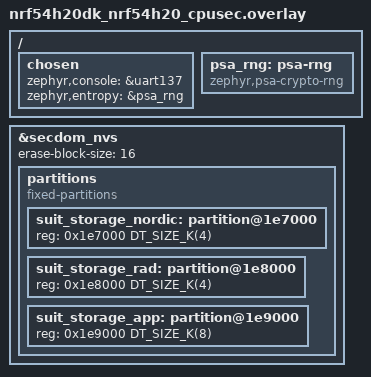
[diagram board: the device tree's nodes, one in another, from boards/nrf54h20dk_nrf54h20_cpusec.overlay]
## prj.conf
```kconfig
#
# Copyright (c) 2024 Nordic Semiconductor ASA
#
# SPDX-License-Identifier: LicenseRef-Nordic-5-Clause
#

CONFIG_ZTEST=y
CONFIG_ZTEST_NEW_API=y

CONFIG_SUIT=y
CONFIG_SUIT_UTILS=y
CONFIG_SUIT_STORAGE=y
# Force SUIT storage memory layout to match nRF54H20-specific implementation.
CONFIG_SUIT_STORAGE_LAYOUT_NRF54H20=y
CONFIG_SUIT_METADATA=y
# nRF54H20 storage uses SHA-256 to protect MPI and NVVs:
CONFIG_SUIT_CRYPTO=y

CONFIG_ZCBOR=y
CONFIG_ZCBOR_CANONICAL=y

CONFIG_FLASH=y
```

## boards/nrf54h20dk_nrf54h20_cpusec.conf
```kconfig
#
# Copyright (c) 2024 Nordic Semiconductor ASA
#
# SPDX-License-Identifier: LicenseRef-Nordic-5-Clause
#

CONFIG_NULL_POINTER_EXCEPTION_DETECTION_NONE=y
CONFIG_SERIAL=y
CONFIG_CONSOLE=y
CONFIG_UART_CONSOLE=y

# This test does not set 'IS_SECURE_DOMAIN_FW'. Hence, we need to enable the
# bare minimum configurations for running on bare metal Secure Domain.
CONFIG_SECDOM_UNIT_TEST_SUPPORT=y

# Logging and printk is using standard UART.
CONFIG_LOG_MODE_DEFERRED=y
CONFIG_LOG_BACKEND_UART=y
CONFIG_LOG_PRINTK=y
CONFIG_LOG_BUFFER_SIZE=8192
```

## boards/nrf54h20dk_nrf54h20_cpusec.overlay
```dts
/*
 * Copyright (c) 2024 Nordic Semiconductor ASA
 *
 * SPDX-License-Identifier: LicenseRef-Nordic-5-Clause
 */

/ {
	chosen {
		zephyr,console = &uart137;
		zephyr,entropy = &psa_rng;
	};

	psa_rng: psa-rng {
		compatible = "zephyr,psa-crypto-rng";
		status = "okay";
	};
};

&secdom_nvs {
	erase-block-size = <16>;

	partitions {
		compatible = "fixed-partitions";
		#address-cells = <1>;
		#size-cells = <1>;

		/* Use the last 32 kB of SecDom SUIT NVM storage. */
		/* Use the first 4kB as area reserved for Secure domain. */
		suit_storage_nordic: partition@1e7000 {
			reg = <0x1e7000 DT_SIZE_K(4)>;
		};

		/* Use the next 4kB as area reserved for Radio domain. */
		suit_storage_rad: partition@1e8000 {
			reg = <0x1e8000 DT_SIZE_K(4)>;
		};

		/* Use the next 8kB as area reserved for Application domain. */
		suit_storage_app: partition@1e9000 {
			reg = <0x1e9000 DT_SIZE_K(8)>;
		};
	};
};
```

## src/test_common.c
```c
/*
 * Copyright (c) 2024 Nordic Semiconductor ASA
 *
 * SPDX-License-Identifier: LicenseRef-Nordic-5-Clause
 */

#include <zephyr/ztest.h>
#include <suit_storage_mpi.h>
#include "test_common.h"

/* RFC4122 uuid5(uuid.NAMESPACE_DNS, 'nordicsemi.com') */
static uint8_t nordic_vid[] = {
	0x76, 0x17, 0xda, 0xa5, 0x71, 0xfd, 0x5a, 0x85,
	0x8f, 0x94, 0xe2, 0x8d, 0x73, 0x5c, 0xe9, 0xf4
};

/* RFC4122 uuid5(nordic_vid, 'nRF54H20_nordic_top') */
static uint8_t nordic_top_cid[] = {
	0xf0, 0x3d, 0x38, 0x5e, 0xa7, 0x31, 0x56, 0x05,
	0xb1, 0x5d, 0x03, 0x7f, 0x6d, 0xa6, 0x09, 0x7f
};

/* RFC4122 uuid5(nordic_vid, 'nRF54H20_sec') */
static uint8_t nordic_sdfw_cid[] = {
	0xd9, 0x6b, 0x40, 0xb7, 0x09, 0x2b, 0x5c, 0xd1,
	0xa5, 0x9f, 0x9a, 0xf8, 0x0c, 0x33, 0x7e, 0xba
};

/* RFC4122 uuid5(nordic_vid, 'nRF54H20_sys') */
static uint8_t nordic_scfw_cid[] = {
	0xc0, 0x8a, 0x25, 0xd7, 0x35, 0xe6, 0x59, 0x2c,
	0xb7, 0xad, 0x43, 0xac, 0xc8, 0xd1, 0xd1, 0xc8
};

/* RFC4122 uuid5(nordic_vid, 'test_sample_root') */
static uint8_t app_root_cid[] = {
	0x97, 0x05, 0x48, 0x23, 0x4c, 0x3d, 0x59, 0xa1,
	0x89, 0x86, 0xa5, 0x46, 0x60, 0xa1, 0x4b, 0x0a,
};

uint8_t nvv_empty[64] = {
	/* 0xFF * 32 */
	0xFF, 0xFF, 0xFF, 0xFF, 0xFF, 0xFF, 0xFF, 0xFF,
	0xFF, 0xFF, 0xFF, 0xFF, 0xFF, 0xFF, 0xFF, 0xFF,
	0xFF, 0xFF, 0xFF, 0xFF, 0xFF, 0xFF, 0xFF, 0xFF,
	0xFF, 0xFF, 0xFF, 0xFF, 0xFF, 0xFF, 0xFF, 0xFF,
	/* SHA-256 */
	0xAF, 0x96, 0x13, 0x76, 0x0F, 0x72, 0x63, 0x5F,
	0xBD, 0xB4, 0x4A, 0x5A, 0x0A, 0x63, 0xC3, 0x9F,
	0x12, 0xAF, 0x30, 0xF9, 0x50, 0xA6, 0xEE, 0x5C,
	0x97, 0x1B, 0xE1, 0x88, 0xE8, 0x9C, 0x40, 0x51,
};

uint8_t nvv_sample[64] = {
	/* sample 8 values */
	0x00, 0x00, 0x00, 0x00, 0xAA, 0xAA, 0xAA, 0xAA,
	0xAA, 0x55, 0xAA, 0x55, 0x00, 0x00, 0x00, 0x01,
	0x01, 0x00, 0x00, 0x00, 0xFF, 0xFF, 0xFF, 0xFF,
	0xAB, 0xCD, 0xEF, 0x98, 0xFF, 0xFF, 0xFF, 0xFF,
	/* SHA-256 */
	0x73, 0xb4, 0x25, 0x20, 0xdf, 0x43, 0x7e, 0xc7,
	0x63, 0xfb, 0xb6, 0x05, 0x70, 0x23, 0x2f, 0xb3,
	0x6a, 0x65, 0xbe, 0x14, 0xcb, 0x2e, 0x83, 0x6a,
	0x3b, 0xc9, 0xfd, 0x87, 0xf6, 0xde, 0x79, 0x05,
};

void erase_area_nordic(void)
{
	/* Clear the whole nordic area */
	const struct device *fdev = DEVICE_DT_GET(DT_CHOSEN(zephyr_flash_controller));
	zassert_not_null(fdev, "Unable to find a driver to modify MPI area");

	int err = flash_erase(fdev, SUIT_STORAGE_NORDIC_OFFSET, SUIT_STORAGE_NORDIC_SIZE);
	zassert_equal(0, err, "Unable to erase nordic area before test execution");
}

void erase_area_rad(void)
{
	/* Clear the whole radio area */
	const struct device *fdev = DEVICE_DT_GET(DT_CHOSEN(zephyr_flash_controller));
	zassert_not_null(fdev, "Unable to find a driver to modify MPI area");

	int err = flash_erase(fdev, SUIT_STORAGE_RAD_OFFSET, SUIT_STORAGE_RAD_SIZE);
	zassert_equal(0, err, "Unable to erase radio core area before test execution");
}

void erase_area_app(void)
{
	/* Clear the whole application area */
	const struct device *fdev = DEVICE_DT_GET(DT_CHOSEN(zephyr_flash_controller));
	zassert_not_null(fdev, "Unable to find a driver to modify MPI area");

	int err = flash_erase(fdev, SUIT_STORAGE_APP_OFFSET, SUIT_STORAGE_APP_SIZE);
	zassert_equal(0, err, "Unable to erase application area before test execution");
}

void erase_area_app_nvv(void)
{
	const struct device *fdev = DEVICE_DT_GET(DT_CHOSEN(zephyr_flash_controller));
	zassert_not_null(fdev, "Unable to find a driver to modify MPI area");

	int err = flash_erase(fdev, SUIT_STORAGE_APP_NVV_OFFSET, SUIT_STORAGE_APP_NVV_SIZE / 2);
	zassert_equal(0, err, "Unable to erase NNV area before test execution");
}

void erase_area_app_nvv_backup(void)
{
	const struct device *fdev = DEVICE_DT_GET(DT_CHOSEN(zephyr_flash_controller));
	zassert_not_null(fdev, "Unable to find a driver to modify MPI area");

	int err = flash_erase(fdev, SUIT_STORAGE_APP_NVV_OFFSET + SUIT_STORAGE_APP_NVV_SIZE / 2,
			      SUIT_STORAGE_APP_NVV_SIZE / 2);
	zassert_equal(0, err, "Unable to erase NNV backup before test execution");
}

void write_area_app_empty_nvv_backup(void)
{
	const struct device *fdev = DEVICE_DT_GET(DT_CHOSEN(zephyr_flash_controller));
	zassert_not_null(fdev, "Unable to find a driver to modify MPI area");

	int err = flash_write(fdev, SUIT_STORAGE_APP_NVV_OFFSET + SUIT_STORAGE_APP_NVV_SIZE / 2,
			      nvv_empty, sizeof(nvv_empty));
	zassert_equal(0, err, "Unable to store empty NVV contents before test execution");
}

void write_area_app_nvv_backup(void)
{
	const struct device *fdev = DEVICE_DT_GET(DT_CHOSEN(zephyr_flash_controller));
	zassert_not_null(fdev, "Unable to find a driver to modify MPI area");

	int err = flash_write(fdev, SUIT_STORAGE_APP_NVV_OFFSET + SUIT_STORAGE_APP_NVV_SIZE / 2,
			      nvv_sample, sizeof(nvv_sample));
	zassert_equal(0, err, "Unable to store empty NVV contents before test execution");
}

void write_area_app_nvv(void)
{
	const struct device *fdev = DEVICE_DT_GET(DT_CHOSEN(zephyr_flash_controller));
	zassert_not_null(fdev, "Unable to find a driver to modify MPI area");

	int err = flash_write(fdev, SUIT_STORAGE_APP_NVV_OFFSET, nvv_sample, sizeof(nvv_sample));
	zassert_equal(0, err, "Unable to store sample NVV contents before test execution");
}

void write_empty_area_app(void)
{
	/* Digest of the content defined in assert_empty_mpi_area_app(). */
	uint8_t app_digest[] = {
		0xd6, 0xc4, 0x94, 0x17, 0xb1, 0xca, 0x0a, 0x67,
		0x14, 0xdc, 0xde, 0x2b, 0x40, 0x01, 0x0c, 0xb7,
		0x49, 0x6d, 0x05, 0xdf, 0x7f, 0x8c, 0x8b, 0x1b,
		0x98, 0x14, 0x09, 0x7e, 0x9d, 0x62, 0xc8, 0xe1,
	};

	/* Write the digest of application area filled with 0xFF */
	const struct device *fdev = DEVICE_DT_GET(DT_CHOSEN(zephyr_flash_controller));
	zassert_not_null(fdev, "Unable to find a driver to modify MPI area");

	int err = flash_write(fdev, SUIT_STORAGE_APP_OFFSET + SUIT_STORAGE_APP_MPI_SIZE, app_digest,
			      sizeof(app_digest));
	zassert_equal(0, err, "Unable to store application MPI digest before test execution");
}

void write_area_app_root(void)
{
	uint8_t mpi_root[] = {
		0x01, /* version */
		0x01, /* downgrade prevention disabled */
		0x02, /* Independent update allowed */
		0x01, /* signature check disabled */
		/* reserved (12) */
		0xFF, 0xFF, 0xFF, 0xFF,
		0xFF, 0xFF, 0xFF, 0xFF, 0xFF, 0xFF, 0xFF, 0xFF,
		/* RFC4122 uuid5(uuid.NAMESPACE_DNS, 'nordicsemi.com') */
		0x76, 0x17, 0xda, 0xa5, 0x71, 0xfd, 0x5a, 0x85,
		0x8f, 0x94, 0xe2, 0x8d, 0x73, 0x5c, 0xe9, 0xf4,
		/* RFC4122 uuid5(nordic_vid, 'test_sample_root') */
		0x97, 0x05, 0x48, 0x23, 0x4c, 0x3d, 0x59, 0xa1,
		0x89, 0x86, 0xa5, 0x46, 0x60, 0xa1, 0x4b, 0x0a,
	};
	/* Digest of the content defined in assert_valid_mpi_area_app(). */
	uint8_t app_digest[] = {
		0xa9, 0xa0, 0xee, 0x40, 0x5f, 0xad, 0x2b, 0xeb,
		0x66, 0x50, 0xdd, 0xa9, 0x97, 0x11, 0x72, 0x98,
		0x2b, 0x17, 0x45, 0x90, 0x16, 0xe1, 0xc7, 0xf5,
		0xc1, 0xdc, 0x3f, 0xb4, 0x58, 0x96, 0x1e, 0x44,
	};

	/* Write the sample application area (just the root MPI) and corresponding digest */
	const struct device *fdev = DEVICE_DT_GET(DT_CHOSEN(zephyr_flash_controller));
	zassert_not_null(fdev, "Unable to find a driver to modify MPI area");

	int err = flash_write(fdev, SUIT_STORAGE_APP_OFFSET, mpi_root, sizeof(mpi_root));
	zassert_equal(0, err,
		      "Unable to store application root MPI contents before test execution");

	err = flash_write(fdev, SUIT_STORAGE_APP_OFFSET + SUIT_STORAGE_APP_MPI_SIZE, app_digest,
			  sizeof(app_digest));
	zassert_equal(0, err, "Unable to store application MPI digest before test execution");
}

void write_area_nordic_root(void)
{
	uintptr_t mpi_root_backup_offset = SUIT_STORAGE_NORDIC_OFFSET + SUIT_STORAGE_RAD_MPI_SIZE;
	uint8_t mpi_root[] = {
		0x01, /* version */
		0x01, /* downgrade prevention disabled */
		0x02, /* Independent update allowed */
		0x01, /* signature check disabled */
		/* reserved (12) */
		0xFF, 0xFF, 0xFF, 0xFF,
		0xFF, 0xFF, 0xFF, 0xFF, 0xFF, 0xFF, 0xFF, 0xFF,
		/* RFC4122 uuid5(uuid.NAMESPACE_DNS, 'nordicsemi.com') */
		0x76, 0x17, 0xda, 0xa5, 0x71, 0xfd, 0x5a, 0x85,
		0x8f, 0x94, 0xe2, 0x8d, 0x73, 0x5c, 0xe9, 0xf4,
		/* RFC4122 uuid5(nordic_vid, 'test_sample_root') */
		0x97, 0x05, 0x48, 0x23, 0x4c, 0x3d, 0x59, 0xa1,
		0x89, 0x86, 0xa5, 0x46, 0x60, 0xa1, 0x4b, 0x0a,
	};
	/* Digest of the content defined in assert_valid_mpi_area_app(). */
	uint8_t app_digest[] = {
		0xa9, 0xa0, 0xee, 0x40, 0x5f, 0xad, 0x2b, 0xeb,
		0x66, 0x50, 0xdd, 0xa9, 0x97, 0x11, 0x72, 0x98,
		0x2b, 0x17, 0x45, 0x90, 0x16, 0xe1, 0xc7, 0xf5,
		0xc1, 0xdc, 0x3f, 0xb4, 0x58, 0x96, 0x1e, 0x44,
	};

	/* Write the sample application backup area (just the root MPI) and corresponding digest */
	const struct device *fdev = DEVICE_DT_GET(DT_CHOSEN(zephyr_flash_controller));
	zassert_not_null(fdev, "Unable to find a driver to modify MPI area");

	int err = flash_write(fdev, mpi_root_backup_offset, mpi_root, sizeof(mpi_root));
	zassert_equal(0, err,
		      "Unable to store application backup root MPI contents before test execution");

	err = flash_write(fdev, mpi_root_backup_offset + SUIT_STORAGE_APP_MPI_SIZE, app_digest,
			  sizeof(app_digest));
	zassert_equal(0, err,
		      "Unable to store application backup MPI digest before test execution");
}

void write_area_nordic_old_root(void)
{
	uintptr_t mpi_root_backup_offset = SUIT_STORAGE_NORDIC_OFFSET + SUIT_STORAGE_RAD_MPI_SIZE;
	uint8_t mpi_root[] = {
		0x01, /* version */
		0x01, /* downgrade prevention disabled */
		0x02, /* Independent update allowed */
		0x01, /* signature check disabled */
		/* reserved (12) */
		0xFF, 0xFF, 0xFF, 0xFF,
		0xFF, 0xFF, 0xFF, 0xFF, 0xFF, 0xFF, 0xFF, 0xFF,
		/* RFC4122 uuid5(uuid.NAMESPACE_DNS, 'nordicsemi.com') */
		0x76, 0x17, 0xda, 0xa5, 0x71, 0xfd, 0x5a, 0x85,
		0x8f, 0x94, 0xe2, 0x8d, 0x73, 0x5c, 0xe9, 0xf4,
		/* 0xAA * 16 */
		0xAA, 0xAA, 0xAA, 0xAA, 0xAA, 0xAA, 0xAA, 0xAA,
		0xAA, 0xAA, 0xAA, 0xAA, 0xAA, 0xAA, 0xAA, 0xAA,
	};
	uint8_t app_digest[] = {
		0xca, 0x4f, 0x80, 0xdc, 0xd1, 0x9b, 0xb2, 0x24,
		0x8e, 0x2b, 0x13, 0xeb, 0x6c, 0xf2, 0xae, 0xd0,
		0x96, 0x28, 0xc2, 0x0c, 0x69, 0xe5, 0xf5, 0x23,
		0x0c, 0x92, 0xd6, 0x2d, 0x36, 0x69, 0x27, 0x58,
	};

	/* Write the sample application backup area (just the root MPI with altered class) and
	 * corresponding digest */
	const struct device *fdev = DEVICE_DT_GET(DT_CHOSEN(zephyr_flash_controller));
	zassert_not_null(fdev, "Unable to find a driver to modify MPI area");

	int err = flash_write(fdev, mpi_root_backup_offset, mpi_root, sizeof(mpi_root));
	zassert_equal(0, err,
		      "Unable to store application backup root MPI contents before test execution");

	err = flash_write(fdev, mpi_root_backup_offset + SUIT_STORAGE_APP_MPI_SIZE, app_digest,
			  sizeof(app_digest));
	zassert_equal(0, err,
		      "Unable to store application backup MPI digest before test execution");
}

void assert_nordic_classes(void)
{
	suit_manifest_class_info_t class_infos[CONFIG_SUIT_STORAGE_N_ENVELOPES];
	size_t class_infos_len = CONFIG_SUIT_STORAGE_N_ENVELOPES;

	/* ASSERT that it is possible to fetch list of supported manifest classes and roles */
	int err = suit_storage_mpi_class_ids_get(class_infos, &class_infos_len);
	zassert_equal(err, SUIT_PLAT_SUCCESS,
		      "Failed to fetch list of supported manifest classes (%d).", err);
	/* ... and MPI reports at least 3 class IDs */
	zassert_true(class_infos_len >= 3,
		     "Invalid number of supported manifest classes (%d < %d).", err, 3);
	/* ... and the Nordic top manifest class is supported */
	zassert_mem_equal(class_infos[0].vendor_id, nordic_vid, sizeof(nordic_vid));
	zassert_mem_equal(class_infos[0].class_id, nordic_top_cid, sizeof(nordic_top_cid));
	zassert_equal(class_infos[0].role, SUIT_MANIFEST_SEC_TOP, "Invalid class role returned: %d",
		      class_infos[0].role);
	/* ... and the Nordic secure domain update & recovery manifest class is supported */
	zassert_mem_equal(class_infos[1].vendor_id, nordic_vid, sizeof(nordic_vid));
	zassert_mem_equal(class_infos[1].class_id, nordic_sdfw_cid, sizeof(nordic_sdfw_cid));
	zassert_equal(class_infos[1].role, SUIT_MANIFEST_SEC_SDFW,
		      "Invalid class role returned: %d", class_infos[3].role);
	/* ... and the Nordic system controller manifest class is supported */
	zassert_mem_equal(class_infos[2].vendor_id, nordic_vid, sizeof(nordic_vid));
	zassert_mem_equal(class_infos[2].class_id, nordic_scfw_cid, sizeof(nordic_scfw_cid));
	zassert_equal(class_infos[2].role, SUIT_MANIFEST_SEC_SYSCTRL,
		      "Invalid class role returned: %d", class_infos[3].role);
}

void assert_sample_root_class(void)
{
	suit_manifest_class_info_t class_infos[CONFIG_SUIT_STORAGE_N_ENVELOPES];
	size_t class_infos_len = CONFIG_SUIT_STORAGE_N_ENVELOPES;

	/* ASSERT that it is possible to fetch list of supported manifest classes and roles */
	int err = suit_storage_mpi_class_ids_get(class_infos, &class_infos_len);
	zassert_equal(err, SUIT_PLAT_SUCCESS,
		      "Failed to fetch list of supported manifest classes (%d).", err);
	/* ... and MPI reports 4 supported class IDs */
	zassert_equal(class_infos_len, 4,
		      "Invalid number of supported manifest classes (%d != %d).", err, 4);
	/* ... and the sample application root manifest class is supported */
	zassert_mem_equal(class_infos[3].vendor_id, nordic_vid, sizeof(nordic_vid));
	zassert_mem_equal(class_infos[3].class_id, app_root_cid, sizeof(app_root_cid));
	zassert_equal(class_infos[3].role, SUIT_MANIFEST_APP_ROOT,
		      "Invalid class role returned: %d", class_infos[3].role);
}

void assert_empty_mpi_area_app(uint8_t *addr, size_t size)
{
	uint8_t empty_mpi_app[] = {
		/* 0xFF * 240 */
		0xFF, 0xFF, 0xFF, 0xFF, 0xFF, 0xFF, 0xFF, 0xFF,
		0xFF, 0xFF, 0xFF, 0xFF, 0xFF, 0xFF, 0xFF, 0xFF,
		0xFF, 0xFF, 0xFF, 0xFF, 0xFF, 0xFF, 0xFF, 0xFF,
		0xFF, 0xFF, 0xFF, 0xFF, 0xFF, 0xFF, 0xFF, 0xFF,
		0xFF, 0xFF, 0xFF, 0xFF, 0xFF, 0xFF, 0xFF, 0xFF,
		0xFF, 0xFF, 0xFF, 0xFF, 0xFF, 0xFF, 0xFF, 0xFF,
		0xFF, 0xFF, 0xFF, 0xFF, 0xFF, 0xFF, 0xFF, 0xFF,
		0xFF, 0xFF, 0xFF, 0xFF, 0xFF, 0xFF, 0xFF, 0xFF,
		0xFF, 0xFF, 0xFF, 0xFF, 0xFF, 0xFF, 0xFF, 0xFF,
		0xFF, 0xFF, 0xFF, 0xFF, 0xFF, 0xFF, 0xFF, 0xFF,
		0xFF, 0xFF, 0xFF, 0xFF, 0xFF, 0xFF, 0xFF, 0xFF,
		0xFF, 0xFF, 0xFF, 0xFF, 0xFF, 0xFF, 0xFF, 0xFF,
		0xFF, 0xFF, 0xFF, 0xFF, 0xFF, 0xFF, 0xFF, 0xFF,
		0xFF, 0xFF, 0xFF, 0xFF, 0xFF, 0xFF, 0xFF, 0xFF,
		0xFF, 0xFF, 0xFF, 0xFF, 0xFF, 0xFF, 0xFF, 0xFF,
		0xFF, 0xFF, 0xFF, 0xFF, 0xFF, 0xFF, 0xFF, 0xFF,
		0xFF, 0xFF, 0xFF, 0xFF, 0xFF, 0xFF, 0xFF, 0xFF,
		0xFF, 0xFF, 0xFF, 0xFF, 0xFF, 0xFF, 0xFF, 0xFF,
		0xFF, 0xFF, 0xFF, 0xFF, 0xFF, 0xFF, 0xFF, 0xFF,
		0xFF, 0xFF, 0xFF, 0xFF, 0xFF, 0xFF, 0xFF, 0xFF,
		0xFF, 0xFF, 0xFF, 0xFF, 0xFF, 0xFF, 0xFF, 0xFF,
		0xFF, 0xFF, 0xFF, 0xFF, 0xFF, 0xFF, 0xFF, 0xFF,
		0xFF, 0xFF, 0xFF, 0xFF, 0xFF, 0xFF, 0xFF, 0xFF,
		0xFF, 0xFF, 0xFF, 0xFF, 0xFF, 0xFF, 0xFF, 0xFF,
		0xFF, 0xFF, 0xFF, 0xFF, 0xFF, 0xFF, 0xFF, 0xFF,
		0xFF, 0xFF, 0xFF, 0xFF, 0xFF, 0xFF, 0xFF, 0xFF,
		0xFF, 0xFF, 0xFF, 0xFF, 0xFF, 0xFF, 0xFF, 0xFF,
		0xFF, 0xFF, 0xFF, 0xFF, 0xFF, 0xFF, 0xFF, 0xFF,
		0xFF, 0xFF, 0xFF, 0xFF, 0xFF, 0xFF, 0xFF, 0xFF,
		0xFF, 0xFF, 0xFF, 0xFF, 0xFF, 0xFF, 0xFF, 0xFF,
		/* SHA-256 */
		0xd6, 0xc4, 0x94, 0x17, 0xb1, 0xca, 0x0a, 0x67,
		0x14, 0xdc, 0xde, 0x2b, 0x40, 0x01, 0x0c, 0xb7,
		0x49, 0x6d, 0x05, 0xdf, 0x7f, 0x8c, 0x8b, 0x1b,
		0x98, 0x14, 0x09, 0x7e, 0x9d, 0x62, 0xc8, 0xe1,
	};

	zassert_equal(size, sizeof(empty_mpi_app), "Incorrect area size (0x%x != 0x%x)", size,
		      sizeof(empty_mpi_app));
	zassert_mem_equal(addr, empty_mpi_app, sizeof(empty_mpi_app),
			  "MPI area does not match empty contents (addr: 0x%lx)", (uintptr_t)addr);
}

void assert_valid_mpi_area_app(uint8_t *addr, size_t size)
{
	uint8_t valid_mpi_app[] = {
		0x01, /* version */
		0x01, /* downgrade prevention disabled */
		0x02, /* Independent update allowed */
		0x01, /* signature check disabled */
		/* reserved (12) */
		0xFF, 0xFF, 0xFF, 0xFF,
		0xFF, 0xFF, 0xFF, 0xFF, 0xFF, 0xFF, 0xFF, 0xFF,
		/* RFC4122 uuid5(uuid.NAMESPACE_DNS, 'nordicsemi.com') */
		0x76, 0x17, 0xda, 0xa5, 0x71, 0xfd, 0x5a, 0x85,
		0x8f, 0x94, 0xe2, 0x8d, 0x73, 0x5c, 0xe9, 0xf4,
		/* RFC4122 uuid5(nordic_vid, 'test_sample_root') */
		0x97, 0x05, 0x48, 0x23, 0x4c, 0x3d, 0x59, 0xa1,
		0x89, 0x86, 0xa5, 0x46, 0x60, 0xa1, 0x4b, 0x0a,
		/* 0xFF * 192 */
		0xFF, 0xFF, 0xFF, 0xFF, 0xFF, 0xFF, 0xFF, 0xFF,
		0xFF, 0xFF, 0xFF, 0xFF, 0xFF, 0xFF, 0xFF, 0xFF,
		0xFF, 0xFF, 0xFF, 0xFF, 0xFF, 0xFF, 0xFF, 0xFF,
		0xFF, 0xFF, 0xFF, 0xFF, 0xFF, 0xFF, 0xFF, 0xFF,
		0xFF, 0xFF, 0xFF, 0xFF, 0xFF, 0xFF, 0xFF, 0xFF,
		0xFF, 0xFF, 0xFF, 0xFF, 0xFF, 0xFF, 0xFF, 0xFF,
		0xFF, 0xFF, 0xFF, 0xFF, 0xFF, 0xFF, 0xFF, 0xFF,
		0xFF, 0xFF, 0xFF, 0xFF, 0xFF, 0xFF, 0xFF, 0xFF,
		0xFF, 0xFF, 0xFF, 0xFF, 0xFF, 0xFF, 0xFF, 0xFF,
		0xFF, 0xFF, 0xFF, 0xFF, 0xFF, 0xFF, 0xFF, 0xFF,
		0xFF, 0xFF, 0xFF, 0xFF, 0xFF, 0xFF, 0xFF, 0xFF,
		0xFF, 0xFF, 0xFF, 0xFF, 0xFF, 0xFF, 0xFF, 0xFF,
		0xFF, 0xFF, 0xFF, 0xFF, 0xFF, 0xFF, 0xFF, 0xFF,
		0xFF, 0xFF, 0xFF, 0xFF, 0xFF, 0xFF, 0xFF, 0xFF,
		0xFF, 0xFF, 0xFF, 0xFF, 0xFF, 0xFF, 0xFF, 0xFF,
		0xFF, 0xFF, 0xFF, 0xFF, 0xFF, 0xFF, 0xFF, 0xFF,
		0xFF, 0xFF, 0xFF, 0xFF, 0xFF, 0xFF, 0xFF, 0xFF,
		0xFF, 0xFF, 0xFF, 0xFF, 0xFF, 0xFF, 0xFF, 0xFF,
		0xFF, 0xFF, 0xFF, 0xFF, 0xFF, 0xFF, 0xFF, 0xFF,
		0xFF, 0xFF, 0xFF, 0xFF, 0xFF, 0xFF, 0xFF, 0xFF,
		0xFF, 0xFF, 0xFF, 0xFF, 0xFF, 0xFF, 0xFF, 0xFF,
		0xFF, 0xFF, 0xFF, 0xFF, 0xFF, 0xFF, 0xFF, 0xFF,
		0xFF, 0xFF, 0xFF, 0xFF, 0xFF, 0xFF, 0xFF, 0xFF,
		0xFF, 0xFF, 0xFF, 0xFF, 0xFF, 0xFF, 0xFF, 0xFF,
		/* SHA-256 */
		0xa9, 0xa0, 0xee, 0x40, 0x5f, 0xad, 0x2b, 0xeb,
		0x66, 0x50, 0xdd, 0xa9, 0x97, 0x11, 0x72, 0x98,
		0x2b, 0x17, 0x45, 0x90, 0x16, 0xe1, 0xc7, 0xf5,
		0xc1, 0xdc, 0x3f, 0xb4, 0x58, 0x96, 0x1e, 0x44,
	};

	zassert_equal(size, sizeof(valid_mpi_app), "Incorrect area size (0x%x != 0x%x)", size,
		      sizeof(valid_mpi_app));
	zassert_mem_equal(addr, valid_mpi_app, sizeof(valid_mpi_app),
			  "MPI area does not match empty contents (addr: 0x%lx)", (uintptr_t)addr);
}
```

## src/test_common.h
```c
/*
 * Copyright (c) 2024 Nordic Semiconductor ASA
 *
 * SPDX-License-Identifier: LicenseRef-Nordic-5-Clause
 */

#include <suit_plat_mem_util.h>

#ifndef TEST_COMMON_H__
#define TEST_COMMON_H__

#define SUIT_STORAGE_NORDIC_ADDRESS suit_plat_mem_nvm_ptr_get(SUIT_STORAGE_NORDIC_OFFSET)
#define SUIT_STORAGE_NORDIC_OFFSET  FIXED_PARTITION_OFFSET(suit_storage_nordic)
#define SUIT_STORAGE_NORDIC_SIZE    FIXED_PARTITION_SIZE(suit_storage_nordic)
#define SUIT_STORAGE_RAD_ADDRESS    suit_plat_mem_nvm_ptr_get(SUIT_STORAGE_RAD_OFFSET)
#define SUIT_STORAGE_RAD_OFFSET	    FIXED_PARTITION_OFFSET(suit_storage_rad)
#define SUIT_STORAGE_RAD_SIZE	    FIXED_PARTITION_SIZE(suit_storage_rad)
#define SUIT_STORAGE_APP_ADDRESS    suit_plat_mem_nvm_ptr_get(SUIT_STORAGE_APP_OFFSET)
#define SUIT_STORAGE_APP_OFFSET	    FIXED_PARTITION_OFFSET(suit_storage_app)
#define SUIT_STORAGE_APP_SIZE	    FIXED_PARTITION_SIZE(suit_storage_app)

#define SUIT_STORAGE_APP_NVV_ADDRESS suit_plat_mem_nvm_ptr_get(SUIT_STORAGE_APP_NVV_OFFSET)
#define SUIT_STORAGE_APP_NVV_OFFSET  (SUIT_STORAGE_APP_OFFSET + 0x380)
#define SUIT_STORAGE_APP_NVV_SIZE    0x80
#define SUIT_STORAGE_APP_MPI_SIZE    0xf0
#define SUIT_STORAGE_RAD_MPI_SIZE    0xb0
#define SUIT_STORAGE_DIGEST_SIZE     0x20

extern uint8_t nvv_empty[64];
extern uint8_t nvv_sample[64];

/** @brief Erase MPI area, assigned for Nordic-controlled manifests.
 */
void erase_area_nordic(void);

/** @brief Erase MPI area, assigned for radio core manifests.
 */
void erase_area_rad(void);

/** @brief Erase MPI area, assigned for application manifests.
 */
void erase_area_app(void);

/** @brief Erase part of MPI area, holding NVV values.
 */
void erase_area_app_nvv(void);

/** @brief Erase part of MPI area, holding NVV backup.
 */
void erase_area_app_nvv_backup(void);

/** @brief Populate part of MPI area, holding NVV backup with initial values.
 */
void write_area_app_empty_nvv_backup(void);

/** @brief Populate part of MPI area, holding NVV backup with sample values.
 */
void write_area_app_nvv_backup(void);

/** @brief Populate part of MPI area, holding NVV values with sample values.
 */
void write_area_app_nvv(void);

/** @brief Populate application MPI area, with ones and the correct digest.
 */
void write_empty_area_app(void);

/** @brief Populate part of application MPI area, with sample root MPI.
 */
void write_area_app_root(void);

/** @brief Populate part of Nordic MPI area, with sample root MPI backup.
 */
void write_area_nordic_root(void);

/** @brief Populate part of Nordic MPI area, with sample outdated root MPI backup.
 */
void write_area_nordic_old_root(void);

/** @brief Assert that all Nordic-controlled MPIs are provisioned.
 */
void assert_nordic_classes(void);

/** @brief Assert that root MPI is provisioned.
 */
void assert_sample_root_class(void);

/** @brief Assert that the area contains empty MPI.
 *
 * @param[in] addr  Address of the area.
 * @param[in] size  Size of the area.
 */
void assert_empty_mpi_area_app(uint8_t *addr, size_t size);

/** @brief Assert that the area contains valid root MPI.
 *
 * @param[in] addr  Address of the area.
 * @param[in] size  Size of the area.
 */
void assert_valid_mpi_area_app(uint8_t *addr, size_t size);

#endif /* TEST_COMMON_H__ */
```

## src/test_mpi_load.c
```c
/*
 * Copyright (c) 2024 Nordic Semiconductor ASA
 *
 * SPDX-License-Identifier: LicenseRef-Nordic-5-Clause
 */

#include <zephyr/ztest.h>
#include <suit_storage_mpi.h>
#include "test_common.h"

static void test_suite_before(void *f)
{
	/* Reinitialize MPI, so it clears all internal state variables. */
	suit_plat_err_t err = suit_storage_mpi_init();
	zassert_equal(err, SUIT_PLAT_SUCCESS, "Failed to init SUIT MPI module (%d)", err);
}

ZTEST_SUITE(suit_storage_nrf54h20_mpi_load_tests, NULL, NULL, test_suite_before, NULL, NULL);

ZTEST(suit_storage_nrf54h20_mpi_load_tests, test_vid_uuid_zeros)
{
	uint8_t mpi[] = {
		0x01, /* version */
		0x01, /* downgrade prevention disabled */
		0x02, /* Independent update allowed */
		0x01, /* signature check disabled */
		/* reserved (12) */
		0xFF, 0xFF, 0xFF, 0xFF,
		0xFF, 0xFF, 0xFF, 0xFF, 0xFF, 0xFF, 0xFF, 0xFF,
		/* 0x00 * 16 */
		0x00, 0x00, 0x00, 0x00, 0x00, 0x00, 0x00, 0x00,
		0x00, 0x00, 0x00, 0x00, 0x00, 0x00, 0x00, 0x00,
		/* RFC4122 uuid5(nordic_vid, 'test_sample_root') */
		0x97, 0x05, 0x48, 0x23, 0x4c, 0x3d, 0x59, 0xa1,
		0x89, 0x86, 0xa5, 0x46, 0x60, 0xa1, 0x4b, 0x0a,
	};

	suit_plat_err_t err =
		suit_storage_mpi_configuration_load(SUIT_MANIFEST_APP_ROOT, mpi, sizeof(mpi));
	zassert_equal(err, SUIT_PLAT_ERR_OUT_OF_BOUNDS,
		      "MPI with UUID filled with zeros should fail to load");
}

ZTEST(suit_storage_nrf54h20_mpi_load_tests, test_vid_uuid_ones)
{
	uint8_t mpi[] = {
		0x01, /* version */
		0x01, /* downgrade prevention disabled */
		0x02, /* Independent update allowed */
		0x01, /* signature check disabled */
		/* reserved (12) */
		0xFF, 0xFF, 0xFF, 0xFF,
		0xFF, 0xFF, 0xFF, 0xFF, 0xFF, 0xFF, 0xFF, 0xFF,
		/* 0xFF * 16 */
		0xFF, 0xFF, 0xFF, 0xFF, 0xFF, 0xFF, 0xFF, 0xFF,
		0xFF, 0xFF, 0xFF, 0xFF, 0xFF, 0xFF, 0xFF, 0xFF,
		/* RFC4122 uuid5(nordic_vid, 'test_sample_root') */
		0x97, 0x05, 0x48, 0x23, 0x4c, 0x3d, 0x59, 0xa1,
		0x89, 0x86, 0xa5, 0x46, 0x60, 0xa1, 0x4b, 0x0a,
	};

	suit_plat_err_t err =
		suit_storage_mpi_configuration_load(SUIT_MANIFEST_APP_ROOT, mpi, sizeof(mpi));
	zassert_equal(err, SUIT_PLAT_ERR_OUT_OF_BOUNDS,
		      "MPI with UUID filled with ones should fail to load");
}

ZTEST(suit_storage_nrf54h20_mpi_load_tests, test_cid_uuid_zeros)
{
	uint8_t mpi[] = {
		0x01, /* version */
		0x01, /* downgrade prevention disabled */
		0x02, /* Independent update allowed */
		0x01, /* signature check disabled */
		/* reserved (12) */
		0xFF, 0xFF, 0xFF, 0xFF,
		0xFF, 0xFF, 0xFF, 0xFF, 0xFF, 0xFF, 0xFF, 0xFF,
		/* RFC4122 uuid5(uuid.NAMESPACE_DNS, 'nordicsemi.com') */
		0x76, 0x17, 0xda, 0xa5, 0x71, 0xfd, 0x5a, 0x85,
		0x8f, 0x94, 0xe2, 0x8d, 0x73, 0x5c, 0xe9, 0xf4,
		/* 0x00 * 16 */
		0x00, 0x00, 0x00, 0x00, 0x00, 0x00, 0x00, 0x00,
		0x00, 0x00, 0x00, 0x00, 0x00, 0x00, 0x00, 0x00,
	};

	suit_plat_err_t err =
		suit_storage_mpi_configuration_load(SUIT_MANIFEST_APP_ROOT, mpi, sizeof(mpi));
	zassert_equal(err, SUIT_PLAT_ERR_OUT_OF_BOUNDS,
		      "MPI with UUID filled with zeros should fail to load");
}

ZTEST(suit_storage_nrf54h20_mpi_load_tests, test_cid_uuid_ones)
{
	uint8_t mpi[] = {
		0x01, /* version */
		0x01, /* downgrade prevention disabled */
		0x02, /* Independent update allowed */
		0x01, /* signature check disabled */
		/* reserved (12) */
		0xFF, 0xFF, 0xFF, 0xFF,
		0xFF, 0xFF, 0xFF, 0xFF, 0xFF, 0xFF, 0xFF, 0xFF,
		/* RFC4122 uuid5(uuid.NAMESPACE_DNS, 'nordicsemi.com') */
		0x76, 0x17, 0xda, 0xa5, 0x71, 0xfd, 0x5a, 0x85,
		0x8f, 0x94, 0xe2, 0x8d, 0x73, 0x5c, 0xe9, 0xf4,
		/* 0xFF * 16 */
		0xFF, 0xFF, 0xFF, 0xFF, 0xFF, 0xFF, 0xFF, 0xFF,
		0xFF, 0xFF, 0xFF, 0xFF, 0xFF, 0xFF, 0xFF, 0xFF,
	};

	suit_plat_err_t err =
		suit_storage_mpi_configuration_load(SUIT_MANIFEST_APP_ROOT, mpi, sizeof(mpi));
	zassert_equal(err, SUIT_PLAT_ERR_OUT_OF_BOUNDS,
		      "MPI with UUID filled with ones should fail to load");
}

ZTEST(suit_storage_nrf54h20_mpi_load_tests, test_recovery_without_updates)
{
	uint8_t mpi[] = {
		0x01, /* version */
		0x01, /* downgrade prevention disabled */
		0x01, /* Independent update disabled */
		0x01, /* signature check disabled */
		/* reserved (12) */
		0xFF, 0xFF, 0xFF, 0xFF,
		0xFF, 0xFF, 0xFF, 0xFF, 0xFF, 0xFF, 0xFF, 0xFF,
		/* RFC4122 uuid5(uuid.NAMESPACE_DNS, 'nordicsemi.com') */
		0x76, 0x17, 0xda, 0xa5, 0x71, 0xfd, 0x5a, 0x85,
		0x8f, 0x94, 0xe2, 0x8d, 0x73, 0x5c, 0xe9, 0xf4,
		/* RFC4122 uuid5(nordic_vid, 'test_sample_root') */
		0x97, 0x05, 0x48, 0x23, 0x4c, 0x3d, 0x59, 0xa1,
		0x89, 0x86, 0xa5, 0x46, 0x60, 0xa1, 0x4b, 0x0a,
	};

	suit_plat_err_t err =
		suit_storage_mpi_configuration_load(SUIT_MANIFEST_APP_RECOVERY, mpi, sizeof(mpi));
	zassert_equal(err, SUIT_PLAT_ERR_UNSUPPORTED,
		      "It should not be possible to block application recovery updates");
}

ZTEST(suit_storage_nrf54h20_mpi_load_tests, test_root_without_updates)
{
	uint8_t mpi[] = {
		0x01, /* version */
		0x01, /* downgrade prevention disabled */
		0x01, /* Independent update disabled */
		0x01, /* signature check disabled */
		/* reserved (12) */
		0xFF, 0xFF, 0xFF, 0xFF,
		0xFF, 0xFF, 0xFF, 0xFF, 0xFF, 0xFF, 0xFF, 0xFF,
		/* RFC4122 uuid5(uuid.NAMESPACE_DNS, 'nordicsemi.com') */
		0x76, 0x17, 0xda, 0xa5, 0x71, 0xfd, 0x5a, 0x85,
		0x8f, 0x94, 0xe2, 0x8d, 0x73, 0x5c, 0xe9, 0xf4,
		/* RFC4122 uuid5(nordic_vid, 'test_sample_root') */
		0x97, 0x05, 0x48, 0x23, 0x4c, 0x3d, 0x59, 0xa1,
		0x89, 0x86, 0xa5, 0x46, 0x60, 0xa1, 0x4b, 0x0a,
	};

	suit_plat_err_t err =
		suit_storage_mpi_configuration_load(SUIT_MANIFEST_APP_ROOT, mpi, sizeof(mpi));
	zassert_equal(err, SUIT_PLAT_ERR_UNSUPPORTED,
		      "It should not be possible to block application root updates");
}

ZTEST(suit_storage_nrf54h20_mpi_load_tests, test_nonerased_reserved)
{
	uint8_t mpi[] = {
		0x01, /* version */
		0x01, /* downgrade prevention disabled */
		0x02, /* Independent update allowed */
		0x01, /* signature check disabled */
		/* reserved (12) */
		0xFF, 0xFF, 0xFF, 0xFF,
		0xFF, 0xFF, 0xFF, 0xFF, 0xFF, 0xFF, 0xFF, 0xFE,
		/* RFC4122 uuid5(uuid.NAMESPACE_DNS, 'nordicsemi.com') */
		0x76, 0x17, 0xda, 0xa5, 0x71, 0xfd, 0x5a, 0x85,
		0x8f, 0x94, 0xe2, 0x8d, 0x73, 0x5c, 0xe9, 0xf4,
		/* RFC4122 uuid5(nordic_vid, 'test_sample_root') */
		0x97, 0x05, 0x48, 0x23, 0x4c, 0x3d, 0x59, 0xa1,
		0x89, 0x86, 0xa5, 0x46, 0x60, 0xa1, 0x4b, 0x0a,
	};

	suit_plat_err_t err =
		suit_storage_mpi_configuration_load(SUIT_MANIFEST_APP_ROOT, mpi, sizeof(mpi));
	zassert_equal(err, SUIT_PLAT_ERR_OUT_OF_BOUNDS,
		      "It should not be possible to load MPI with nonerase reserved fields");
}

ZTEST(suit_storage_nrf54h20_mpi_load_tests, test_empty_new_version)
{
	uint8_t mpi[] = {
		0x02, /* unsupported version */
		0xFF, 0xFF, 0xFF, 0xFF, 0xFF, 0xFF, 0xFF,
		0xFF, 0xFF, 0xFF, 0xFF, 0xFF, 0xFF, 0xFF, 0xFF,
		0xFF, 0xFF, 0xFF, 0xFF, 0xFF, 0xFF, 0xFF, 0xFF,
		0xFF, 0xFF, 0xFF, 0xFF, 0xFF, 0xFF, 0xFF, 0xFF,
		0xFF, 0xFF, 0xFF, 0xFF, 0xFF, 0xFF, 0xFF, 0xFF,
		0xFF, 0xFF, 0xFF, 0xFF, 0xFF, 0xFF, 0xFF, 0xFF,
	};

	suit_plat_err_t err =
		suit_storage_mpi_configuration_load(SUIT_MANIFEST_APP_ROOT, mpi, sizeof(mpi));
	zassert_equal(err, SUIT_PLAT_ERR_OUT_OF_BOUNDS,
		      "It should not be possible to load MPI with unsupported version");
}

ZTEST(suit_storage_nrf54h20_mpi_load_tests, test_downgrade_prevention_zero)
{
	uint8_t mpi[] = {
		0x01, /* version */
		0x00, /* unknown downgrade prevention policy */
		0x02, /* Independent update allowed */
		0x01, /* signature check disabled */
		/* reserved (12) */
		0xFF, 0xFF, 0xFF, 0xFF,
		0xFF, 0xFF, 0xFF, 0xFF, 0xFF, 0xFF, 0xFF, 0xFF,
		/* RFC4122 uuid5(uuid.NAMESPACE_DNS, 'nordicsemi.com') */
		0x76, 0x17, 0xda, 0xa5, 0x71, 0xfd, 0x5a, 0x85,
		0x8f, 0x94, 0xe2, 0x8d, 0x73, 0x5c, 0xe9, 0xf4,
		/* RFC4122 uuid5(nordic_vid, 'test_sample_root') */
		0x97, 0x05, 0x48, 0x23, 0x4c, 0x3d, 0x59, 0xa1,
		0x89, 0x86, 0xa5, 0x46, 0x60, 0xa1, 0x4b, 0x0a,
	};

	suit_plat_err_t err =
		suit_storage_mpi_configuration_load(SUIT_MANIFEST_APP_ROOT, mpi, sizeof(mpi));
	zassert_equal(
		err, SUIT_PLAT_ERR_OUT_OF_BOUNDS,
		"It should not be possible to load MPI with unknown downgrade prevention policy");
}

ZTEST(suit_storage_nrf54h20_mpi_load_tests, test_independent_updateability_zero)
{
	uint8_t mpi[] = {
		0x01, /* version */
		0x01, /* downgrade prevention disabled */
		0x00, /* unknown independent update policy */
		0x01, /* signature check disabled */
		/* reserved (12) */
		0xFF, 0xFF, 0xFF, 0xFF,
		0xFF, 0xFF, 0xFF, 0xFF, 0xFF, 0xFF, 0xFF, 0xFF,
		/* RFC4122 uuid5(uuid.NAMESPACE_DNS, 'nordicsemi.com') */
		0x76, 0x17, 0xda, 0xa5, 0x71, 0xfd, 0x5a, 0x85,
		0x8f, 0x94, 0xe2, 0x8d, 0x73, 0x5c, 0xe9, 0xf4,
		/* RFC4122 uuid5(nordic_vid, 'test_sample_root') */
		0x97, 0x05, 0x48, 0x23, 0x4c, 0x3d, 0x59, 0xa1,
		0x89, 0x86, 0xa5, 0x46, 0x60, 0xa1, 0x4b, 0x0a,
	};

	suit_plat_err_t err =
		suit_storage_mpi_configuration_load(SUIT_MANIFEST_APP_ROOT, mpi, sizeof(mpi));
	zassert_equal(
		err, SUIT_PLAT_ERR_OUT_OF_BOUNDS,
		"It should not be possible to load MPI with unknown independent update policy");
}

ZTEST(suit_storage_nrf54h20_mpi_load_tests, test_signature_check_zero)
{
	uint8_t mpi[] = {
		0x01, /* version */
		0x01, /* downgrade prevention disabled */
		0x02, /* Independent update allowed */
		0x00, /* unknown signature check policy */
		/* reserved (12) */
		0xFF, 0xFF, 0xFF, 0xFF,
		0xFF, 0xFF, 0xFF, 0xFF, 0xFF, 0xFF, 0xFF, 0xFF,
		/* RFC4122 uuid5(uuid.NAMESPACE_DNS, 'nordicsemi.com') */
		0x76, 0x17, 0xda, 0xa5, 0x71, 0xfd, 0x5a, 0x85,
		0x8f, 0x94, 0xe2, 0x8d, 0x73, 0x5c, 0xe9, 0xf4,
		/* RFC4122 uuid5(nordic_vid, 'test_sample_root') */
		0x97, 0x05, 0x48, 0x23, 0x4c, 0x3d, 0x59, 0xa1,
		0x89, 0x86, 0xa5, 0x46, 0x60, 0xa1, 0x4b, 0x0a,
	};

	suit_plat_err_t err =
		suit_storage_mpi_configuration_load(SUIT_MANIFEST_APP_ROOT, mpi, sizeof(mpi));
	zassert_equal(err, SUIT_PLAT_ERR_OUT_OF_BOUNDS,
		      "It should not be possible to load MPI with unknown signature check policy");
}

ZTEST(suit_storage_nrf54h20_mpi_load_tests, test_fake_nordic_top_manifest)
{
	uint8_t mpi[] = {
		0x01, /* version */
		0x01, /* downgrade prevention disabled */
		0x02, /* Independent update allowed */
		0x01, /* signature check disabled */
		/* reserved (12) */
		0xFF, 0xFF, 0xFF, 0xFF,
		0xFF, 0xFF, 0xFF, 0xFF, 0xFF, 0xFF, 0xFF, 0xFF,
		/* RFC4122 uuid5(uuid.NAMESPACE_DNS, 'nordicsemi.com') */
		0x76, 0x17, 0xda, 0xa5, 0x71, 0xfd, 0x5a, 0x85,
		0x8f, 0x94, 0xe2, 0x8d, 0x73, 0x5c, 0xe9, 0xf4,
		/* RFC4122 uuid5(nordic_vid, 'nRF54H20_nordic_top') */
		0xf0, 0x3d, 0x38, 0x5e, 0xa7, 0x31, 0x56, 0x05,
		0xb1, 0x5d, 0x03, 0x7f, 0x6d, 0xa6, 0x09, 0x7f,
	};

	/* GIVEN the Nordic top manifest is already loaded */
	suit_plat_err_t err =
		suit_storage_mpi_configuration_load(SUIT_MANIFEST_SEC_TOP, mpi, sizeof(mpi));
	zassert_equal(err, SUIT_PLAT_SUCCESS,
		      "Unable to load Nordic top manifest prior test execution (err: %d)", err);

	/* WHEN application loads ROOT manifest with Nordic top class ID */
	err = suit_storage_mpi_configuration_load(SUIT_MANIFEST_APP_ROOT, mpi, sizeof(mpi));

	/* THEN application slot is not loaded */
	zassert_equal(err, SUIT_PLAT_ERR_EXISTS,
		      "It should not be possible to load root MPI with Nordic top class ID");
}

ZTEST(suit_storage_nrf54h20_mpi_load_tests, test_two_root_manifests)
{
	uint8_t mpi[] = {
		0x01, /* version */
		0x01, /* downgrade prevention disabled */
		0x02, /* Independent update allowed */
		0x01, /* signature check disabled */
		/* reserved (12) */
		0xFF, 0xFF, 0xFF, 0xFF,
		0xFF, 0xFF, 0xFF, 0xFF, 0xFF, 0xFF, 0xFF, 0xFF,
		/* RFC4122 uuid5(uuid.NAMESPACE_DNS, 'nordicsemi.com') */
		0x76, 0x17, 0xda, 0xa5, 0x71, 0xfd, 0x5a, 0x85,
		0x8f, 0x94, 0xe2, 0x8d, 0x73, 0x5c, 0xe9, 0xf4,
		/* RFC4122 uuid5(nordic_vid, 'test_sample_root') */
		0x97, 0x05, 0x48, 0x23, 0x4c, 0x3d, 0x59, 0xa1,
		0x89, 0x86, 0xa5, 0x46, 0x60, 0xa1, 0x4b, 0x0a,
	};

	/* GIVEN the ROOT manifest is already loaded */
	suit_plat_err_t err =
		suit_storage_mpi_configuration_load(SUIT_MANIFEST_APP_ROOT, mpi, sizeof(mpi));
	zassert_equal(err, SUIT_PLAT_SUCCESS,
		      "Unable to load root manifest prior test execution (err: %d)", err);

	/* WHEN application loads ROOT manifest from a different slot */
	err = suit_storage_mpi_configuration_load(SUIT_MANIFEST_APP_ROOT, mpi, sizeof(mpi));

	/* THEN the second slot is not loaded */
	zassert_equal(err, SUIT_PLAT_ERR_EXISTS,
		      "It should not be possible to load root MPI twice");
}

ZTEST(suit_storage_nrf54h20_mpi_load_tests, test_too_many_roles)
{
	suit_manifest_role_t roles[] = {
		SUIT_MANIFEST_SEC_TOP,
		SUIT_MANIFEST_SEC_SDFW,
		SUIT_MANIFEST_SEC_SYSCTRL,
		SUIT_MANIFEST_APP_ROOT,
		SUIT_MANIFEST_APP_RECOVERY,
		SUIT_MANIFEST_APP_LOCAL_1,
		SUIT_MANIFEST_APP_LOCAL_2,
		SUIT_MANIFEST_APP_LOCAL_3,
		SUIT_MANIFEST_RAD_RECOVERY,
		SUIT_MANIFEST_RAD_LOCAL_1,
		SUIT_MANIFEST_RAD_LOCAL_2,
	};
	uint8_t mpi[] = {
		0x01, /* version */
		0x01, /* downgrade prevention disabled */
		0x02, /* Independent update allowed */
		0x01, /* signature check disabled */
		/* reserved (12) */
		0xFF, 0xFF, 0xFF, 0xFF,
		0xFF, 0xFF, 0xFF, 0xFF, 0xFF, 0xFF, 0xFF, 0xFF,
		/* RFC4122 uuid5(uuid.NAMESPACE_DNS, 'nordicsemi.com') */
		0x76, 0x17, 0xda, 0xa5, 0x71, 0xfd, 0x5a, 0x85,
		0x8f, 0x94, 0xe2, 0x8d, 0x73, 0x5c, 0xe9, 0xf4,
		/* RFC4122 uuid5(nordic_vid, 'test_sample_root') */
		0x97, 0x05, 0x48, 0x23, 0x4c, 0x3d, 0x59, 0xa1,
		0x89, 0x86, 0xa5, 0x46, 0x60, 0xa1, 0x4b, 0x0a,
	};
	uint8_t mpi_array[sizeof(mpi) * ARRAY_SIZE(roles)];

	for (size_t i = 0; i < ARRAY_SIZE(roles); i++) {
		/* Fake CID so each entry is different */
		memcpy(&mpi_array[i * sizeof(mpi)], mpi, sizeof(mpi));
		mpi_array[i * sizeof(mpi) + sizeof(mpi) - 1] = roles[i];
	}

	/* Check that the test will not exceed the array with roles. */
	zassert_true(ARRAY_SIZE(roles) > CONFIG_SUIT_STORAGE_N_ENVELOPES,
		     "Unable to execute test: role list does not exceed MPI limits (%d >= %d)",
		     CONFIG_SUIT_STORAGE_N_ENVELOPES, ARRAY_SIZE(roles));

	/* GIVEN all slots in MPI are used */
	for (size_t i = 0; i < CONFIG_SUIT_STORAGE_N_ENVELOPES; i++) {
		suit_plat_err_t err = suit_storage_mpi_configuration_load(
			roles[i], &mpi_array[i * sizeof(mpi)], sizeof(mpi));
		zassert_equal(err, SUIT_PLAT_SUCCESS,
			      "Unable to load manifest with role %d at index %d prior test "
			      "execution (err: %d)",
			      roles[i], i, err);
	}

	for (size_t i = CONFIG_SUIT_STORAGE_N_ENVELOPES; i < ARRAY_SIZE(roles); i++) {
		/* WHEN application loads next manifest */
		suit_plat_err_t err = suit_storage_mpi_configuration_load(
			roles[i], &mpi_array[i * sizeof(mpi)], sizeof(mpi));

		/* THEN the it is not loaded */
		zassert_equal(
			err, SUIT_PLAT_ERR_SIZE,
			"It should not be possible to load more MPIs than configured (index: %d)",
			i);
	}
}
```

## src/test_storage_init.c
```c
/*
 * Copyright (c) 2024 Nordic Semiconductor ASA
 *
 * SPDX-License-Identifier: LicenseRef-Nordic-5-Clause
 */

#include <zephyr/ztest.h>
#include <suit_storage.h>
#include <suit_storage_mpi.h>
#include <suit_storage_nvv.h>
#include "test_common.h"

ZTEST_SUITE(suit_storage_nrf54h20_init_tests, NULL, NULL, NULL, NULL, NULL);

ZTEST(suit_storage_nrf54h20_init_tests, test_empty_storage)
{
	uint8_t nvv_erased[SUIT_STORAGE_APP_NVV_SIZE];
	memset(nvv_erased, 0xff, sizeof(nvv_erased));

	/* GIVEN the whole SUIT storage area is erased (unprovisioned device) */
	erase_area_nordic();
	erase_area_rad();
	erase_area_app();

	/* WHEN storage module is initialized */
	int err = suit_storage_init();

	/* THEN digest of the application MPI and it's backup does not match... */
	int exp_err = SUIT_PLAT_ERR_CRASH;
	/* ... and an error code is returned */
	zassert_equal(err, exp_err, "Unexpected error code returned (%d).", err);
	/* ... and NVV area is not initialized */
	zassert_mem_equal(SUIT_STORAGE_APP_NVV_ADDRESS, nvv_erased, SUIT_STORAGE_APP_NVV_SIZE);
	/* ... and Nordic class IDs are supported */
	assert_nordic_classes();
}

ZTEST(suit_storage_nrf54h20_init_tests, test_empty_app_with_digest)
{
	uint8_t nvv_erased[SUIT_STORAGE_APP_NVV_SIZE];
	memset(nvv_erased, 0xff, sizeof(nvv_erased));

	/* GIVEN the device is provisioned with empty application MPI */
	erase_area_nordic();
	erase_area_rad();
	erase_area_app();
	write_empty_area_app();

	/* WHEN storage module is initialized */
	int err = suit_storage_init();

	/* THEN digest of the application MPI matches... */
	/* ... and the application MPI is copied into application backup area */
	assert_empty_mpi_area_app(SUIT_STORAGE_APP_ADDRESS,
				  SUIT_STORAGE_APP_MPI_SIZE + SUIT_STORAGE_DIGEST_SIZE);
	assert_empty_mpi_area_app(SUIT_STORAGE_NORDIC_ADDRESS + SUIT_STORAGE_RAD_MPI_SIZE,
				  SUIT_STORAGE_APP_MPI_SIZE + SUIT_STORAGE_DIGEST_SIZE);
	/* ... and parsing of the root MPI entry fails */
	int exp_err = SUIT_PLAT_ERR_NOT_FOUND;
	/* ... and an error code is returned */
	zassert_equal(err, exp_err, "Unexpected error code returned (%d).", err);
	/* ... and NVV area is not initialized */
	zassert_mem_equal(SUIT_STORAGE_APP_NVV_ADDRESS, nvv_erased, SUIT_STORAGE_APP_NVV_SIZE);
	/* ... and Nordic class IDs are supported */
	assert_nordic_classes();
}

ZTEST(suit_storage_nrf54h20_init_tests, test_app_with_root)
{
	/* GIVEN the device is provisioned with application MPI with root config */
	erase_area_nordic();
	erase_area_rad();
	erase_area_app();
	write_area_app_root();

	/* WHEN storage module is initialized */
	int err = suit_storage_init();

	/* THEN digest of the application MPI matches... */
	/* ... and the application MPI is copied into application backup area */
	assert_valid_mpi_area_app(SUIT_STORAGE_APP_ADDRESS,
				  SUIT_STORAGE_APP_MPI_SIZE + SUIT_STORAGE_DIGEST_SIZE);
	assert_valid_mpi_area_app(SUIT_STORAGE_NORDIC_ADDRESS + SUIT_STORAGE_RAD_MPI_SIZE,
				  SUIT_STORAGE_APP_MPI_SIZE + SUIT_STORAGE_DIGEST_SIZE);
	/* ... and parsing of the root MPI succeeds */
	int exp_err = SUIT_PLAT_SUCCESS;
	/* ... and NVV area digest does not match */
	/* ... and NVV area is initialized with default values (0xFF) and digest */
	zassert_mem_equal(SUIT_STORAGE_APP_NVV_ADDRESS, nvv_empty, SUIT_STORAGE_APP_NVV_SIZE / 2);
	/* ... and NVV area is copied into NVV backup area */
	zassert_mem_equal(SUIT_STORAGE_APP_NVV_ADDRESS + SUIT_STORAGE_APP_NVV_SIZE / 2, nvv_empty,
			  SUIT_STORAGE_APP_NVV_SIZE / 2);
	/* ... and initialization succeeds */
	zassert_equal(err, exp_err, "Failed to initialize SUIT storage (%d).", err);
	/* ... and Nordic class IDs are supported */
	assert_nordic_classes();
	/* ... and sample root class is supported */
	assert_sample_root_class();
}

ZTEST(suit_storage_nrf54h20_init_tests, test_app_with_root_backup)
{
	/* GIVEN the device was provisioned with application MPI with root config */
	erase_area_nordic();
	write_area_nordic_root();
	/* .. and the application area was erased after the backup was created */
	erase_area_rad();
	erase_area_app();

	/* WHEN storage module is initialized */
	int err = suit_storage_init();

	/* THEN digest of the application MPI does not match... */
	/* ... and the application MPI is copied from backup area */
	assert_valid_mpi_area_app(SUIT_STORAGE_APP_ADDRESS,
				  SUIT_STORAGE_APP_MPI_SIZE + SUIT_STORAGE_DIGEST_SIZE);
	assert_valid_mpi_area_app(SUIT_STORAGE_NORDIC_ADDRESS + SUIT_STORAGE_RAD_MPI_SIZE,
				  SUIT_STORAGE_APP_MPI_SIZE + SUIT_STORAGE_DIGEST_SIZE);
	/* ... and parsing of the root MPI succeeds */
	int exp_err = SUIT_PLAT_SUCCESS;
	/* ... and NVV area digest does not match */
	/* ... and NVV area is initialized with default values (0xFF) and digest */
	zassert_mem_equal(SUIT_STORAGE_APP_NVV_ADDRESS, nvv_empty, SUIT_STORAGE_APP_NVV_SIZE / 2);
	/* ... and NVV area is copied into NVV backup area */
	zassert_mem_equal(SUIT_STORAGE_APP_NVV_ADDRESS + SUIT_STORAGE_APP_NVV_SIZE / 2, nvv_empty,
			  SUIT_STORAGE_APP_NVV_SIZE / 2);
	/* ... and initialization succeeds */
	zassert_equal(err, exp_err, "Failed to initialize SUIT storage (%d).", err);
	/* ... and Nordic class IDs are supported */
	assert_nordic_classes();
	/* ... and sample root class is supported */
	assert_sample_root_class();
}

ZTEST(suit_storage_nrf54h20_init_tests, test_app_with_old_root_nvv_backup)
{
	/* GIVEN the device was provisioned with application MPI with old root config */
	erase_area_nordic();
	write_area_nordic_old_root();
	/* .. and the device is provisioned with new application MPI with root config */
	erase_area_rad();
	erase_area_app();
	write_area_app_empty_nvv_backup();
	write_area_app_nvv();
	write_area_app_root();

	/* WHEN storage module is initialized */
	int err = suit_storage_init();

	/* THEN digest of the application MPI matches... */
	/* ... and the application MPI is copied into application backup area */
	assert_valid_mpi_area_app(SUIT_STORAGE_APP_ADDRESS,
				  SUIT_STORAGE_APP_MPI_SIZE + SUIT_STORAGE_DIGEST_SIZE);
	assert_valid_mpi_area_app(SUIT_STORAGE_NORDIC_ADDRESS + SUIT_STORAGE_RAD_MPI_SIZE,
				  SUIT_STORAGE_APP_MPI_SIZE + SUIT_STORAGE_DIGEST_SIZE);
	/* ... and parsing of the root MPI succeeds */
	int exp_err = SUIT_PLAT_SUCCESS;
	/* ... and NVV area digest does matches */
	/* ... and NVV area is not modified */
	zassert_mem_equal(SUIT_STORAGE_APP_NVV_ADDRESS, nvv_sample, SUIT_STORAGE_APP_NVV_SIZE / 2);
	/* ... and NVV area backup is updated */
	zassert_mem_equal(SUIT_STORAGE_APP_NVV_ADDRESS + SUIT_STORAGE_APP_NVV_SIZE / 2, nvv_sample,
			  SUIT_STORAGE_APP_NVV_SIZE / 2);
	/* ... and initialization succeeds */
	zassert_equal(err, exp_err, "Failed to initialize SUIT storage (%d).", err);
	/* ... and Nordic class IDs are supported */
	assert_nordic_classes();
	/* ... and sample root class is supported */
	assert_sample_root_class();
}

ZTEST(suit_storage_nrf54h20_init_tests, test_app_corrupted_nvv)
{
	/* GIVEN the device is provisioned with application MPI with root config */
	erase_area_nordic();
	write_area_nordic_root();
	/* .. and NVV area is erased */
	erase_area_rad();
	erase_area_app();
	write_area_app_root();
	/* .. and NVV backup is present */
	write_area_app_nvv_backup();

	/* WHEN storage module is initialized */
	int err = suit_storage_init();

	/* THEN digest of the application MPI matches... */
	/* ... and the application MPI is the same as application backup area */
	assert_valid_mpi_area_app(SUIT_STORAGE_APP_ADDRESS,
				  SUIT_STORAGE_APP_MPI_SIZE + SUIT_STORAGE_DIGEST_SIZE);
	assert_valid_mpi_area_app(SUIT_STORAGE_NORDIC_ADDRESS + SUIT_STORAGE_RAD_MPI_SIZE,
				  SUIT_STORAGE_APP_MPI_SIZE + SUIT_STORAGE_DIGEST_SIZE);
	/* ... and parsing of the root MPI succeeds */
	int exp_err = SUIT_PLAT_SUCCESS;
	/* ... and NVV area digest does not match */
	/* ... and NVV area is recovered from backup */
	zassert_mem_equal(SUIT_STORAGE_APP_NVV_ADDRESS, nvv_sample, SUIT_STORAGE_APP_NVV_SIZE / 2);
	/* ... and NVV area backup is not modified */
	zassert_mem_equal(SUIT_STORAGE_APP_NVV_ADDRESS + SUIT_STORAGE_APP_NVV_SIZE / 2, nvv_sample,
			  SUIT_STORAGE_APP_NVV_SIZE / 2);
	/* ... and initialization succeeds */
	zassert_equal(err, exp_err, "Failed to initialize SUIT storage (%d).", err);
	/* ... and Nordic class IDs are supported */
	assert_nordic_classes();
	/* ... and sample root class is supported */
	assert_sample_root_class();
}

ZTEST(suit_storage_nrf54h20_init_tests, test_app_corrupted_nvv_backup)
{
	/* GIVEN the device is provisioned with application MPI with root config */
	erase_area_nordic();
	write_area_nordic_root();
	/* .. and NVV backup is erased */
	erase_area_rad();
	erase_area_app();
	write_area_app_root();
	/* .. and NVV is present */
	write_area_app_nvv();

	/* WHEN storage module is initialized */
	int err = suit_storage_init();

	/* THEN digest of the application MPI matches... */
	/* ... and the application MPI is the same as application backup area */
	assert_valid_mpi_area_app(SUIT_STORAGE_APP_ADDRESS,
				  SUIT_STORAGE_APP_MPI_SIZE + SUIT_STORAGE_DIGEST_SIZE);
	assert_valid_mpi_area_app(SUIT_STORAGE_NORDIC_ADDRESS + SUIT_STORAGE_RAD_MPI_SIZE,
				  SUIT_STORAGE_APP_MPI_SIZE + SUIT_STORAGE_DIGEST_SIZE);
	/* ... and parsing of the root MPI succeeds */
	int exp_err = SUIT_PLAT_SUCCESS;
	/* ... and NVV area digest matches */
	/* ... and NVV area is not modified */
	zassert_mem_equal(SUIT_STORAGE_APP_NVV_ADDRESS, nvv_sample, SUIT_STORAGE_APP_NVV_SIZE / 2);
	/* ... and NVV area backup is updated */
	zassert_mem_equal(SUIT_STORAGE_APP_NVV_ADDRESS + SUIT_STORAGE_APP_NVV_SIZE / 2, nvv_sample,
			  SUIT_STORAGE_APP_NVV_SIZE / 2);
	/* ... and initialization succeeds */
	zassert_equal(err, exp_err, "Failed to initialize SUIT storage (%d).", err);
	/* ... and Nordic class IDs are supported */
	assert_nordic_classes();
	/* ... and sample root class is supported */
	assert_sample_root_class();
}
```
